VERSION "HIPBNYYYYYYYYYYYYYYYYYYYYYYYYYYYYYYYYYYYYY/4/%%%/4/'%**4YYY///"

NS_ :

BS_:

BU_: WS200 MCN_Powertrain Front_MCN Mid_MCN Rear_MCN IMU_MCN BIM1 BIM2 BIM3 BIM4 Computer BIM5 Rider_Controls GPS MCN1 MCN2 MCN3 Drive_Controls BIM6 BoschABS IMU

BO_ 1024 WS200IDInfo: 8 WS200
 SG_ TritiumID : 0|32@1+ (1,0) [0|0] "" Vector__XXX
 SG_ SerialNumber : 32|32@1+ (1,0) [0|0] "" Vector__XXX

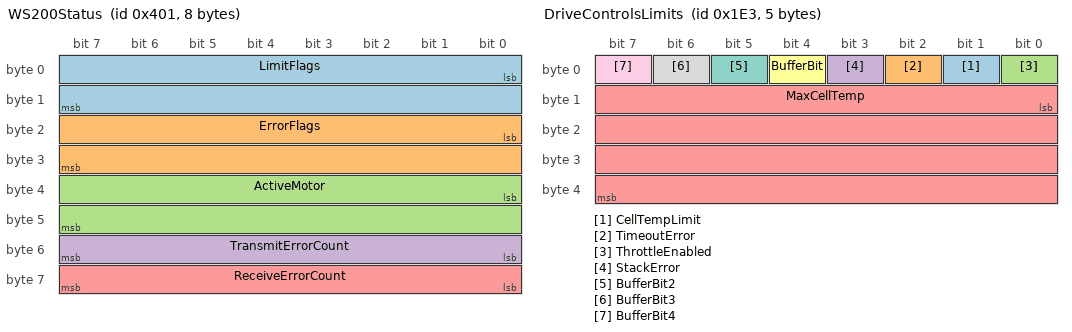
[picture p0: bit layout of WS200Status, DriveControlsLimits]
BO_ 1025 WS200Status: 8 WS200
 SG_ LimitFlags : 0|16@1+ (1,0) [0|0] "" Vector__XXX
 SG_ ErrorFlags : 16|16@1+ (1,0) [0|0] "" Vector__XXX
 SG_ ActiveMotor : 32|16@1+ (1,0) [0|0] "" Vector__XXX
 SG_ TransmitErrorCount : 48|8@1+ (1,0) [0|0] "" Vector__XXX
 SG_ ReceiveErrorCount : 56|8@1+ (1,0) [0|0] "" Vector__XXX

BO_ 1026 WS200BusMeasurement: 8 WS200
 SG_ BusVoltage : 0|32@1- (1,0) [0|0] "" Vector__XXX
 SG_ BusCurrent : 32|32@1- (1,0) [0|0] "" Vector__XXX

BO_ 1027 VelocityMeasurement: 8 WS200
 SG_ MotorVelocity : 0|32@1- (1,0) [0|0] "" Vector__XXX
 SG_ VehicleVelocity : 32|32@1- (1,0) [0|0] "" Vector__XXX

BO_ 1028 PhaseCurrent: 8 WS200
 SG_ PhaseCurrentB : 0|32@1- (1,0) [0|0] "" Vector__XXX
 SG_ PhaseCurrentC : 32|32@1- (1,0) [0|0] "" Vector__XXX

BO_ 1029 MotorVoltage: 8 WS200
 SG_ Vq : 0|32@1- (1,0) [0|0] "" Vector__XXX
 SG_ Vd : 32|32@1- (1,0) [0|0] "" Vector__XXX

BO_ 1030 MotorCurrent: 8 WS200
 SG_ Iq : 0|32@1- (1,0) [0|0] "" Vector__XXX
 SG_ Id : 32|32@1- (1,0) [0|0] "" Vector__XXX

BO_ 1031 MotorBackEMF: 8 WS200
 SG_ BEMFq : 0|32@1- (1,0) [0|0] "" Vector__XXX
 SG_ BEMFd : 32|32@1- (1,0) [0|0] "" Vector__XXX

BO_ 1032 WS200Rail15V: 8 WS200
 SG_ Supply15V : 32|32@1- (1,0) [0|0] "" Vector__XXX
 SG_ Reserved15V : 0|32@1- (1,0) [0|0] "" Vector__XXX

BO_ 1033 WS200LowRail: 8 WS200
 SG_ Rail2V : 0|32@1- (1,0) [0|0] "" Vector__XXX
 SG_ Rail3V : 32|32@1- (1,0) [0|0] "" Vector__XXX

BO_ 1035 WS200MotorTemp: 8 WS200
 SG_ IPMPhaseATemp : 32|32@1- (1,0) [0|0] "" Vector__XXX
 SG_ MotorTemp : 0|32@1- (1,0) [0|0] "" Vector__XXX

BO_ 1036 WS200DSPBoardTemp: 8 WS200
 SG_ IPMPhaseBTemp : 0|32@1- (1,0) [0|0] "" Vector__XXX
 SG_ DSPBoardTemp : 32|32@1- (1,0) [0|0] "" Vector__XXX

BO_ 1037 WS200PhaseCTemp: 8 WS200
 SG_ IMPPhaseCTemp : 32|32@1- (1,0) [0|0] "" Vector__XXX
 SG_ Reserved : 0|32@1- (1,0) [0|0] "" Vector__XXX

BO_ 1038 WS200BusAmpHours: 8 WS200
 SG_ DCBusAmpHours : 32|32@1- (1,0) [0|0] "" Vector__XXX
 SG_ Odometer : 0|32@1- (1,0) [0|0] "" Vector__XXX

BO_ 1039 SlipSpeed: 8 WS200
 SG_ SlipSpeed : 0|32@1- (1,0) [0|0] "" Vector__XXX
 SG_ Reserved : 32|32@1- (1,0) [0|0] "" Vector__XXX

BO_ 551 Steering: 4 MCN1
 SG_ SteeringAngle : 0|32@1- (1,0) [0|0] "" Vector__XXX

BO_ 552 AmbientMeasurements: 8 MCN1
 SG_ AmbientTemp : 0|32@1- (1,0) [0|0] "" Vector__XXX
 SG_ AmbientPressure : 32|32@1- (1,0) [0|0] "" Vector__XXX

BO_ 1281 MotorDriveCommand: 8 Drive_Controls
 SG_ MotorRPMSetpoint : 0|32@1- (1,0) [0|4000] "" Vector__XXX
 SG_ MotorCurrentSetpoint : 32|32@1- (1,0) [0|1] "" Vector__XXX

BO_ 483 DriveControlsLimits: 5 Drive_Controls
 SG_ CellTempLimit : 1|1@1+ (1,0) [0|1] "" Vector__XXX
 SG_ TimeoutError : 2|1@1+ (1,0) [0|1] "" Vector__XXX
 SG_ ThrottleEnabled : 0|1@1+ (1,0) [0|0] "" Vector__XXX
 SG_ StackError : 3|1@1+ (1,0) [0|0] "" Vector__XXX
 SG_ MaxCellTemp : 8|32@1- (1,0) [0|0] "" Vector__XXX
 SG_ BufferBit : 4|1@1+ (1,0) [0|0] "" Vector__XXX
 SG_ BufferBit2 : 5|1@1+ (1,0) [0|0] "" Vector__XXX
 SG_ BufferBit3 : 6|1@1+ (1,0) [0|0] "" Vector__XXX
 SG_ BufferBit4 : 7|1@1+ (1,0) [0|0] "" Vector__XXX

BO_ 750 BIM1Stats1: 6 BIM1
 SG_ BIM1MaxCellVoltage : 0|16@1+ (1,0) [0|0] "" Vector__XXX
 SG_ BIM1MaxCellNumber : 16|8@1+ (1,0) [0|0] "" Vector__XXX
 SG_ BIM1MinCellVoltage : 32|16@1+ (1,0) [0|0] "" Vector__XXX
 SG_ BIM1MinCellNumber : 48|8@1+ (1,0) [0|0] "" Vector__XXX
 SG_ BIM1Stat1reserve : 24|8@1+ (1,0) [0|0] "" Vector__XXX

BO_ 751 BIM1Stats2: 5 BIM1
 SG_ BIM1AvgCellVoltage : 0|16@1+ (1,0) [0|0] "" Vector__XXX
 SG_ BIM1StdDevCellVoltage : 16|16@1+ (1,0) [0|0] "" Vector__XXX
 SG_ BIM1NumOfBalancingCells : 32|8@1+ (1,0) [0|0] "" Vector__XXX

BO_ 752 BIM2Stats1: 6 BIM2
 SG_ BIM2MaxCellVoltage : 0|16@1+ (1,0) [0|0] "" Vector__XXX
 SG_ BIM2MaxCellNumber : 16|8@1+ (1,0) [0|0] "" Vector__XXX
 SG_ BIM2MinCellVoltage : 32|16@1+ (1,0) [0|0] "" Vector__XXX
 SG_ BIM2MinCellNumber : 48|8@1+ (1,0) [0|0] "" Vector__XXX
 SG_ BIM2Stat1reserve : 24|8@1+ (1,0) [0|0] "" Vector__XXX

BO_ 753 BIM2Stats2: 5 BIM2
 SG_ BIM2AvgCellVoltage : 0|16@1+ (1,0) [0|0] "" Vector__XXX
 SG_ BIM2StdDevCellVoltage : 16|16@1+ (1,0) [0|0] "" Vector__XXX
 SG_ BIM2NumOfBalancingCells : 32|8@1+ (1,0) [0|0] "" Vector__XXX

BO_ 754 BIM3Stats1: 6 BIM3
 SG_ BIM3MaxCellVoltage : 0|16@1+ (1,0) [0|0] "" Vector__XXX
 SG_ BIM3MaxCellNumber : 16|8@1+ (1,0) [0|0] "" Vector__XXX
 SG_ BIM3MinCellVoltage : 32|16@1+ (1,0) [0|0] "" Vector__XXX
 SG_ BIM3MinCellNumber : 48|8@1+ (1,0) [0|0] "" Vector__XXX
 SG_ BIM3Stat1reserve : 24|8@1+ (1,0) [0|0] "" Vector__XXX

BO_ 755 BIM3Stats2: 5 BIM3
 SG_ BIM3AvgCellVoltage : 0|16@1+ (1,0) [0|0] "" Vector__XXX
 SG_ BIM3StdDevVoltage : 16|16@1+ (1,0) [0|0] "" Vector__XXX
 SG_ BIM3NumOfBalancingCells : 32|8@1+ (1,0) [0|0] "" Vector__XXX

BO_ 756 BIM4Stats1: 6 BIM4
 SG_ BIM4MaxCellVoltage : 0|16@1+ (1,0) [0|0] "" Vector__XXX
 SG_ BIM4MaxCellNumber : 16|8@1+ (1,0) [0|0] "" Vector__XXX
 SG_ BIM4MinCellVoltage : 32|16@1+ (1,0) [0|0] "" Vector__XXX
 SG_ BIM4MinCellNumber : 48|8@1+ (1,0) [0|0] "" Vector__XXX
 SG_ BIM4Stat1reserve : 24|8@1+ (1,0) [0|0] "" Vector__XXX

BO_ 757 BIM4Stats2: 5 BIM4
 SG_ BIM4AvgCellVoltage : 0|16@1+ (1,0) [0|0] "" Vector__XXX
 SG_ BIM4StdDevVoltage : 16|16@1+ (1,0) [0|0] "" Vector__XXX
 SG_ BIM4NumOfBalancingCells : 32|8@1+ (1,0) [0|0] "" Vector__XXX

BO_ 758 BIM5Stats1: 6 BIM5
 SG_ BIM5MaxCellVoltage : 0|16@1+ (1,0) [0|0] "" Vector__XXX
 SG_ BIM5MaxCellNumber : 16|8@1+ (1,0) [0|0] "" Vector__XXX
 SG_ BIM5MinCellVoltage : 32|16@1+ (1,0) [0|0] "" Vector__XXX
 SG_ BIM5MinCellNumber : 48|8@1+ (1,0) [0|0] "" Vector__XXX
 SG_ BIM5Stat1reserve : 24|8@1+ (1,0) [0|0] "" Vector__XXX

BO_ 759 BIM5Stats2: 5 BIM5
 SG_ BIM5AvgCellVoltage : 0|16@1+ (1,0) [0|0] "" Vector__XXX
 SG_ BIM5StdDevVoltage : 16|16@1+ (1,0) [0|0] "" Vector__XXX
 SG_ BIM5NumOfBalancingCells : 32|8@1+ (1,0) [0|0] "" Vector__XXX

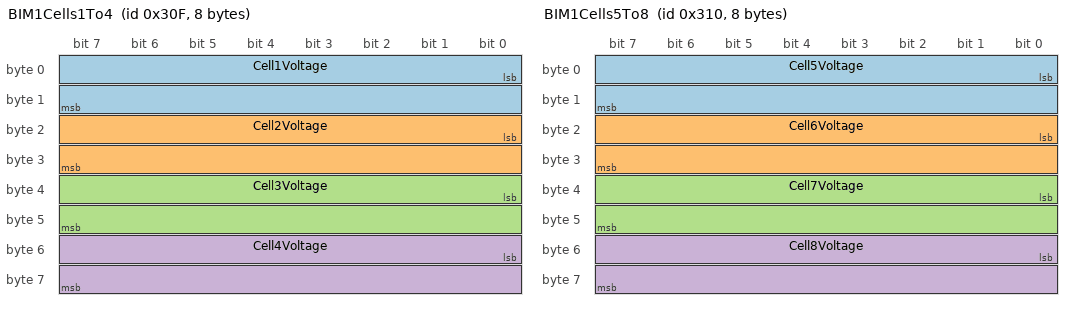
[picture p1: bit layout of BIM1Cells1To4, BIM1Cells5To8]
BO_ 783 BIM1Cells1To4: 8 BIM1
 SG_ Cell1Voltage : 0|16@1- (1,0) [0|0] "" Vector__XXX
 SG_ Cell2Voltage : 16|16@1- (1,0) [0|0] "" Vector__XXX
 SG_ Cell3Voltage : 32|16@1- (1,0) [0|0] "" Vector__XXX
 SG_ Cell4Voltage : 48|16@1- (1,0) [0|0] "" Vector__XXX

BO_ 784 BIM1Cells5To8: 8 BIM1
 SG_ Cell5Voltage : 0|16@1- (1,0) [0|0] "" Vector__XXX
 SG_ Cell6Voltage : 16|16@1- (1,0) [0|0] "" Vector__XXX
 SG_ Cell7Voltage : 32|16@1- (1,0) [0|0] "" Vector__XXX
 SG_ Cell8Voltage : 48|16@1- (1,0) [0|0] "" Vector__XXX

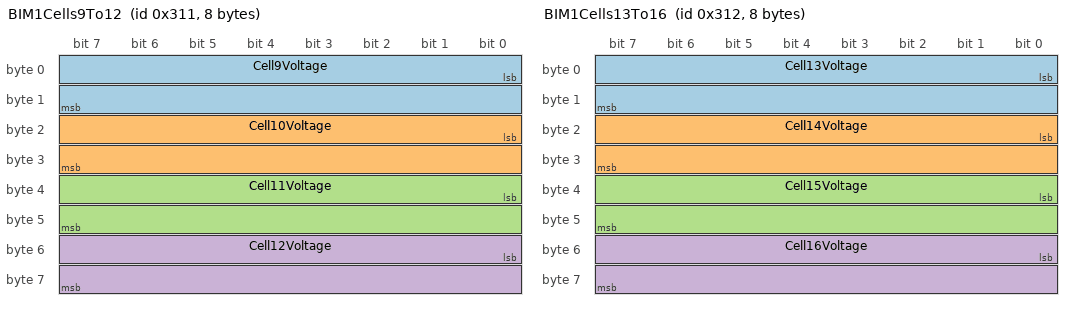
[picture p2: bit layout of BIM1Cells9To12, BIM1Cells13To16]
BO_ 785 BIM1Cells9To12: 8 BIM1
 SG_ Cell9Voltage : 0|16@1- (1,0) [0|0] "" Vector__XXX
 SG_ Cell10Voltage : 16|16@1- (1,0) [0|0] "" Vector__XXX
 SG_ Cell11Voltage : 32|16@1- (1,0) [0|0] "" Vector__XXX
 SG_ Cell12Voltage : 48|16@1- (1,0) [0|0] "" Vector__XXX

BO_ 786 BIM1Cells13To16: 8 BIM1
 SG_ Cell13Voltage : 0|16@1- (1,0) [0|0] "" Vector__XXX
 SG_ Cell14Voltage : 16|16@1- (1,0) [0|0] "" Vector__XXX
 SG_ Cell15Voltage : 32|16@1- (1,0) [0|0] "" Vector__XXX
 SG_ Cell16Voltage : 48|16@1- (1,0) [0|0] "" Vector__XXX

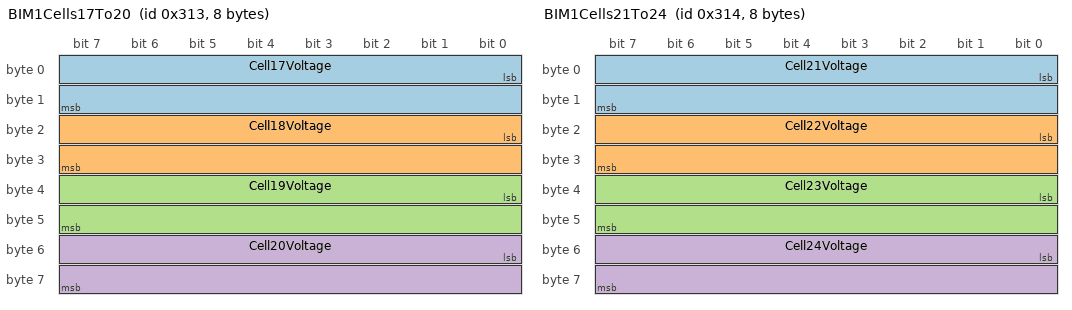
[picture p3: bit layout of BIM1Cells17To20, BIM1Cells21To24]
BO_ 787 BIM1Cells17To20: 8 BIM1
 SG_ Cell17Voltage : 0|16@1- (1,0) [0|0] "" Vector__XXX
 SG_ Cell18Voltage : 16|16@1- (1,0) [0|0] "" Vector__XXX
 SG_ Cell19Voltage : 32|16@1- (1,0) [0|0] "" Vector__XXX
 SG_ Cell20Voltage : 48|16@1- (1,0) [0|0] "" Vector__XXX

BO_ 788 BIM1Cells21To24: 8 BIM1
 SG_ Cell21Voltage : 0|16@1- (1,0) [0|0] "" Vector__XXX
 SG_ Cell22Voltage : 16|16@1- (1,0) [0|0] "" Vector__XXX
 SG_ Cell23Voltage : 32|16@1- (1,0) [0|0] "" Vector__XXX
 SG_ Cell24Voltage : 48|16@1- (1,0) [0|0] "" Vector__XXX

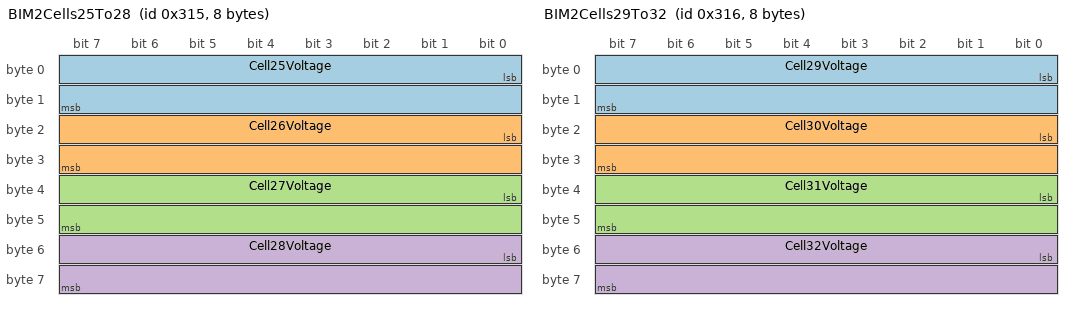
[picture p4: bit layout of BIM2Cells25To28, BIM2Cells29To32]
BO_ 789 BIM2Cells25To28: 8 BIM2
 SG_ Cell25Voltage : 0|16@1- (1,0) [0|0] "" Vector__XXX
 SG_ Cell26Voltage : 16|16@1- (1,0) [0|0] "" Vector__XXX
 SG_ Cell27Voltage : 32|16@1- (1,0) [0|0] "" Vector__XXX
 SG_ Cell28Voltage : 48|16@1- (1,0) [0|0] "" Vector__XXX

BO_ 790 BIM2Cells29To32: 8 BIM2
 SG_ Cell29Voltage : 0|16@1- (1,0) [0|0] "" Vector__XXX
 SG_ Cell30Voltage : 16|16@1- (1,0) [0|0] "" Vector__XXX
 SG_ Cell31Voltage : 32|16@1- (1,0) [0|0] "" Vector__XXX
 SG_ Cell32Voltage : 48|16@1- (1,0) [0|0] "" Vector__XXX

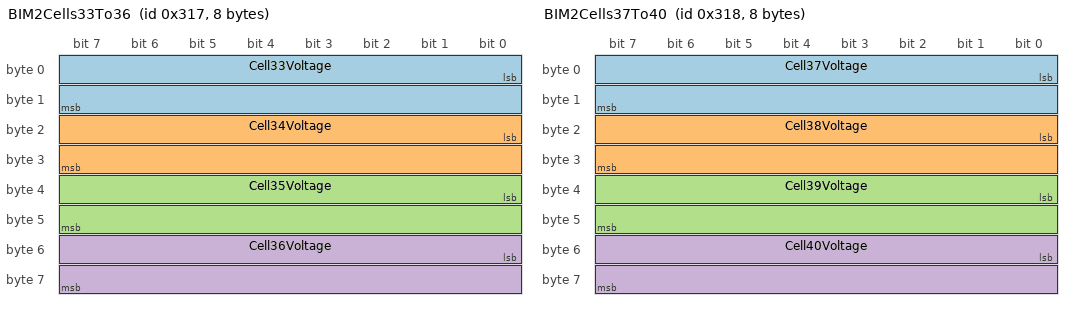
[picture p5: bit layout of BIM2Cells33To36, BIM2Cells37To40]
BO_ 791 BIM2Cells33To36: 8 BIM2
 SG_ Cell33Voltage : 0|16@1- (1,0) [0|0] "" Vector__XXX
 SG_ Cell34Voltage : 16|16@1- (1,0) [0|0] "" Vector__XXX
 SG_ Cell35Voltage : 32|16@1- (1,0) [0|0] "" Vector__XXX
 SG_ Cell36Voltage : 48|16@1- (1,0) [0|0] "" Vector__XXX

BO_ 792 BIM2Cells37To40: 8 BIM2
 SG_ Cell37Voltage : 0|16@1- (1,0) [0|0] "" Vector__XXX
 SG_ Cell38Voltage : 16|16@1- (1,0) [0|0] "" Vector__XXX
 SG_ Cell39Voltage : 32|16@1- (1,0) [0|0] "" Vector__XXX
 SG_ Cell40Voltage : 48|16@1- (1,0) [0|0] "" Vector__XXX

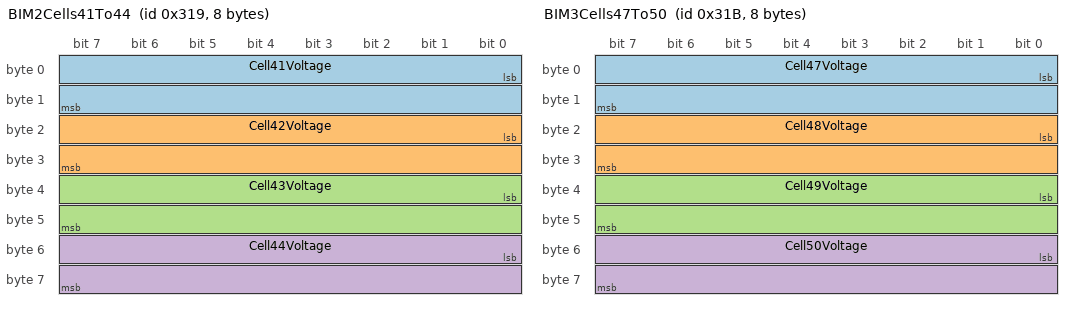
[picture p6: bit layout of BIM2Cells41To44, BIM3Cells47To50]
BO_ 793 BIM2Cells41To44: 8 BIM2
 SG_ Cell41Voltage : 0|16@1- (1,0) [0|0] "" Vector__XXX
 SG_ Cell42Voltage : 16|16@1- (1,0) [0|0] "" Vector__XXX
 SG_ Cell43Voltage : 32|16@1- (1,0) [0|0] "" Vector__XXX
 SG_ Cell44Voltage : 48|16@1- (1,0) [0|0] "" Vector__XXX

BO_ 794 BIM2Cells45To46: 4 BIM2
 SG_ Cell45Voltage : 0|16@1- (1,0) [0|0] "" Vector__XXX
 SG_ Cell46Voltage : 16|16@1- (1,0) [0|0] "" Vector__XXX
 SG_ Cell47Voltage : 32|16@1- (1,0) [0|0] "" Vector__XXX
 SG_ Cell48Voltage : 48|16@1- (1,0) [0|0] "" Vector__XXX

BO_ 795 BIM3Cells47To50: 8 BIM3
 SG_ Cell47Voltage : 0|16@1- (1,0) [0|0] "" Vector__XXX
 SG_ Cell48Voltage : 16|16@1- (1,0) [0|0] "" Vector__XXX
 SG_ Cell49Voltage : 32|16@1- (1,0) [0|0] "" Vector__XXX
 SG_ Cell50Voltage : 48|16@1- (1,0) [0|0] "" Vector__XXX

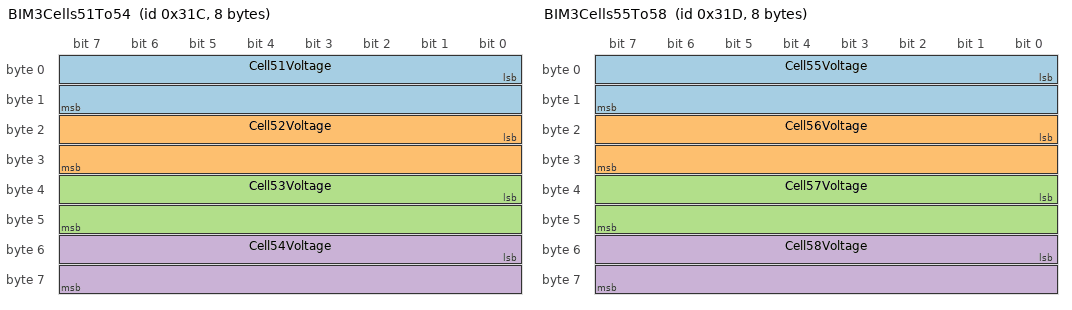
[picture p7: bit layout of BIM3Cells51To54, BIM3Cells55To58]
BO_ 796 BIM3Cells51To54: 8 BIM3
 SG_ Cell51Voltage : 0|16@1- (1,0) [0|0] "" Vector__XXX
 SG_ Cell52Voltage : 16|16@1- (1,0) [0|0] "" Vector__XXX
 SG_ Cell53Voltage : 32|16@1- (1,0) [0|0] "" Vector__XXX
 SG_ Cell54Voltage : 48|16@1- (1,0) [0|0] "" Vector__XXX

BO_ 797 BIM3Cells55To58: 8 BIM3
 SG_ Cell55Voltage : 0|16@1- (1,0) [0|0] "" Vector__XXX
 SG_ Cell56Voltage : 16|16@1- (1,0) [0|0] "" Vector__XXX
 SG_ Cell57Voltage : 32|16@1- (1,0) [0|0] "" Vector__XXX
 SG_ Cell58Voltage : 48|16@1- (1,0) [0|0] "" Vector__XXX

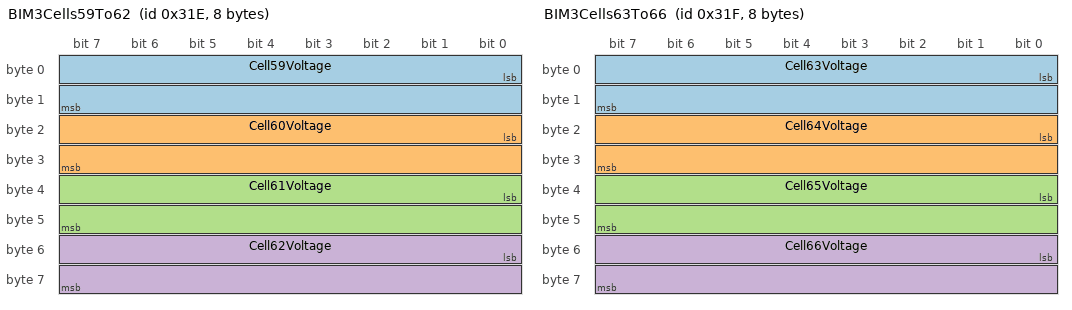
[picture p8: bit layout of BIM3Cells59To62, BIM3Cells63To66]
BO_ 798 BIM3Cells59To62: 8 BIM3
 SG_ Cell59Voltage : 0|16@1- (1,0) [0|0] "" Vector__XXX
 SG_ Cell60Voltage : 16|16@1- (1,0) [0|0] "" Vector__XXX
 SG_ Cell61Voltage : 32|16@1- (1,0) [0|0] "" Vector__XXX
 SG_ Cell62Voltage : 48|16@1- (1,0) [0|0] "" Vector__XXX

BO_ 799 BIM3Cells63To66: 8 BIM3
 SG_ Cell63Voltage : 0|16@1- (1,0) [0|0] "" Vector__XXX
 SG_ Cell64Voltage : 16|16@1- (1,0) [0|0] "" Vector__XXX
 SG_ Cell65Voltage : 32|16@1- (1,0) [0|0] "" Vector__XXX
 SG_ Cell66Voltage : 48|16@1- (1,0) [0|0] "" Vector__XXX

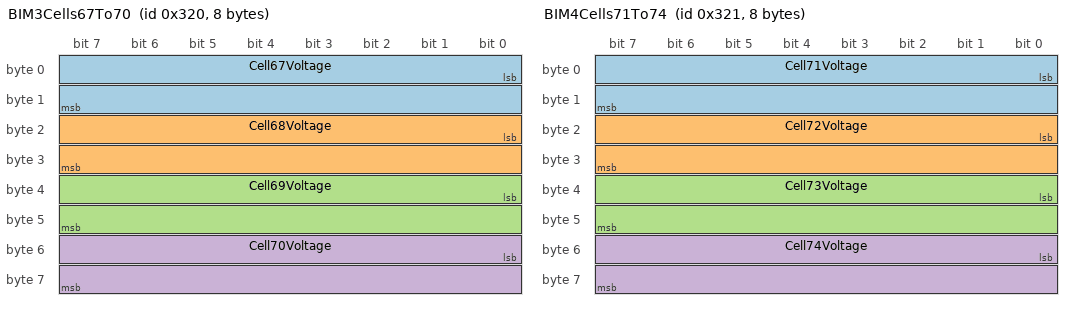
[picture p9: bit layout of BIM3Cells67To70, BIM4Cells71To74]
BO_ 800 BIM3Cells67To70: 8 BIM3
 SG_ Cell67Voltage : 0|16@1- (1,0) [0|0] "" Vector__XXX
 SG_ Cell68Voltage : 16|16@1- (1,0) [0|0] "" Vector__XXX
 SG_ Cell69Voltage : 32|16@1- (1,0) [0|0] "" Vector__XXX
 SG_ Cell70Voltage : 48|16@1- (1,0) [0|0] "" Vector__XXX

BO_ 801 BIM4Cells71To74: 8 BIM4
 SG_ Cell71Voltage : 0|16@1- (1,0) [0|0] "" Vector__XXX
 SG_ Cell72Voltage : 16|16@1- (1,0) [0|0] "" Vector__XXX
 SG_ Cell73Voltage : 32|16@1- (1,0) [0|0] "" Vector__XXX
 SG_ Cell74Voltage : 48|16@1- (1,0) [0|0] "" Vector__XXX

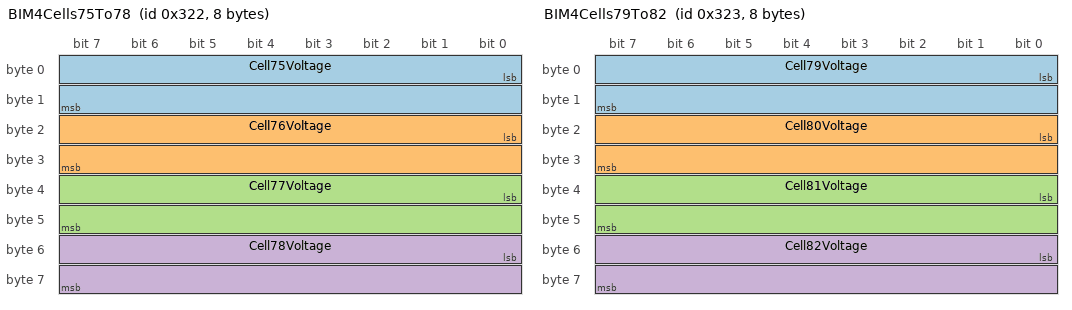
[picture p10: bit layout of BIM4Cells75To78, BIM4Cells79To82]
BO_ 802 BIM4Cells75To78: 8 BIM4
 SG_ Cell75Voltage : 0|16@1- (1,0) [0|0] "" Vector__XXX
 SG_ Cell76Voltage : 16|16@1- (1,0) [0|0] "" Vector__XXX
 SG_ Cell77Voltage : 32|16@1- (1,0) [0|0] "" Vector__XXX
 SG_ Cell78Voltage : 48|16@1- (1,0) [0|0] "" Vector__XXX

BO_ 803 BIM4Cells79To82: 8 BIM4
 SG_ Cell79Voltage : 0|16@1- (1,0) [0|0] "" Vector__XXX
 SG_ Cell80Voltage : 16|16@1- (1,0) [0|0] "" Vector__XXX
 SG_ Cell81Voltage : 32|16@1- (1,0) [0|0] "" Vector__XXX
 SG_ Cell82Voltage : 48|16@1- (1,0) [0|0] "" Vector__XXX

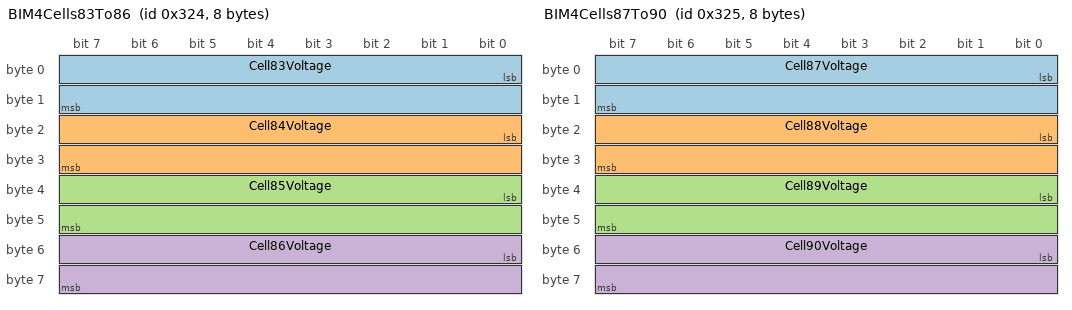
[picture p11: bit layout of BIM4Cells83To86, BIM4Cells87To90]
BO_ 804 BIM4Cells83To86: 8 BIM4
 SG_ Cell83Voltage : 0|16@1- (1,0) [0|0] "" Vector__XXX
 SG_ Cell84Voltage : 16|16@1- (1,0) [0|0] "" Vector__XXX
 SG_ Cell85Voltage : 32|16@1- (1,0) [0|0] "" Vector__XXX
 SG_ Cell86Voltage : 48|16@1- (1,0) [0|0] "" Vector__XXX

BO_ 805 BIM4Cells87To90: 8 BIM4
 SG_ Cell87Voltage : 0|16@1- (1,0) [0|0] "" Vector__XXX
 SG_ Cell88Voltage : 16|16@1- (1,0) [0|0] "" Vector__XXX
 SG_ Cell89Voltage : 32|16@1- (1,0) [0|0] "" Vector__XXX
 SG_ Cell90Voltage : 48|16@1- (1,0) [0|0] "" Vector__XXX

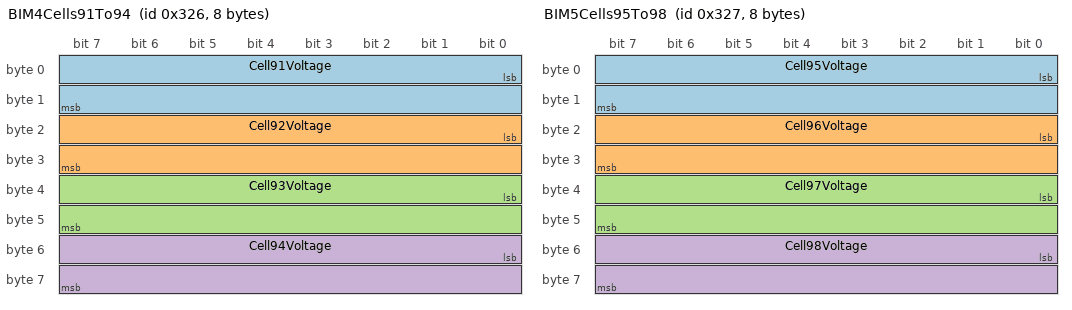
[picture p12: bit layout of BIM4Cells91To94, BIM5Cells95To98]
BO_ 806 BIM4Cells91To94: 8 BIM4
 SG_ Cell91Voltage : 0|16@1- (1,0) [0|0] "" Vector__XXX
 SG_ Cell92Voltage : 16|16@1- (1,0) [0|0] "" Vector__XXX
 SG_ Cell93Voltage : 32|16@1- (1,0) [0|0] "" Vector__XXX
 SG_ Cell94Voltage : 48|16@1- (1,0) [0|0] "" Vector__XXX

BO_ 807 BIM5Cells95To98: 8 BIM5
 SG_ Cell95Voltage : 0|16@1- (1,0) [0|0] "" Vector__XXX
 SG_ Cell96Voltage : 16|16@1- (1,0) [0|0] "" Vector__XXX
 SG_ Cell97Voltage : 32|16@1- (1,0) [0|0] "" Vector__XXX
 SG_ Cell98Voltage : 48|16@1- (1,0) [0|0] "" Vector__XXX

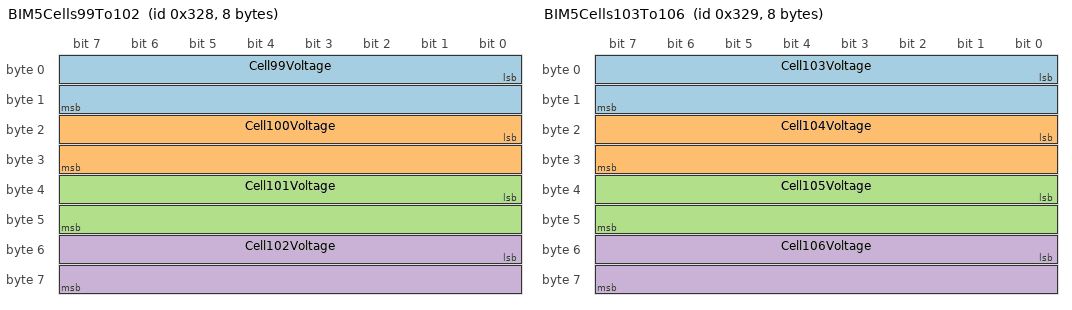
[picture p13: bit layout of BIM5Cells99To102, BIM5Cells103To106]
BO_ 808 BIM5Cells99To102: 8 BIM5
 SG_ Cell99Voltage : 0|16@1- (1,0) [0|0] "" Vector__XXX
 SG_ Cell100Voltage : 16|16@1- (1,0) [0|0] "" Vector__XXX
 SG_ Cell101Voltage : 32|16@1- (1,0) [0|0] "" Vector__XXX
 SG_ Cell102Voltage : 48|16@1- (1,0) [0|0] "" Vector__XXX

BO_ 809 BIM5Cells103To106: 8 BIM5
 SG_ Cell103Voltage : 0|16@1- (1,0) [0|0] "" Vector__XXX
 SG_ Cell104Voltage : 16|16@1- (1,0) [0|0] "" Vector__XXX
 SG_ Cell105Voltage : 32|16@1- (1,0) [0|0] "" Vector__XXX
 SG_ Cell106Voltage : 48|16@1- (1,0) [0|0] "" Vector__XXX

BO_ 826 BIM1Temps2: 8 BIM1
 SG_ CellTemp3 : 0|32@1- (1,0) [0|0] "" Vector__XXX
 SG_ CellTemp4 : 32|32@1- (1,0) [0|0] "" Vector__XXX

BO_ 827 BIM1Temps3: 8 BIM1
 SG_ CellTemp5 : 0|32@1- (1,0) [0|0] "" Vector__XXX
 SG_ CellTemp6 : 32|32@1- (1,0) [0|0] "" Vector__XXX

BO_ 828 BIM1Temps4: 8 BIM1
 SG_ CellTemp7 : 0|32@1- (1,0) [0|0] "" Vector__XXX
 SG_ CellTemp8 : 32|32@1- (1,0) [0|0] "" Vector__XXX

BO_ 829 BIM2Temps1: 8 BIM2
 SG_ CellTemp9 : 0|32@1- (1,0) [0|0] "" Vector__XXX
 SG_ CellTemp10 : 32|32@1- (1,0) [0|0] "" Vector__XXX

BO_ 830 BIM2Temps2: 8 BIM2
 SG_ CellTemp11 : 0|32@1- (1,0) [0|0] "" Vector__XXX
 SG_ CellTemp12 : 32|32@1- (1,0) [0|0] "" Vector__XXX

BO_ 831 BIM2Temps3: 8 BIM2
 SG_ CellTemp13 : 0|32@1- (1,0) [0|0] "" Vector__XXX
 SG_ CellTemp14 : 32|32@1- (1,0) [0|0] "" Vector__XXX

BO_ 832 BIM2Temps4: 8 BIM2
 SG_ CellTemp15 : 0|32@1- (1,0) [0|0] "" Vector__XXX
 SG_ CellTemp16 : 32|32@1- (1,0) [0|0] "" Vector__XXX

BO_ 833 BIM3Temps1: 8 BIM3
 SG_ CellTemp17 : 0|32@1- (1,0) [0|0] "" Vector__XXX
 SG_ CellTemp18 : 32|32@1- (1,0) [0|0] "" Vector__XXX

BO_ 834 BIM3Temps2: 8 BIM3
 SG_ CellTemp19 : 0|32@1- (1,0) [0|0] "" Vector__XXX
 SG_ CellTemp20 : 32|32@1- (1,0) [0|0] "" Vector__XXX

BO_ 835 BIM3Temps3: 8 BIM3
 SG_ CellTemp21 : 0|32@1- (1,0) [0|0] "" Vector__XXX
 SG_ CellTemp22 : 32|32@1- (1,0) [0|0] "" Vector__XXX

BO_ 836 BIM3Temps4: 8 BIM3
 SG_ CellTemp23 : 0|32@1- (1,0) [0|0] "" Vector__XXX
 SG_ CellTemp24 : 32|32@1- (1,0) [0|0] "" Vector__XXX

BO_ 837 BIM4Temps1: 8 BIM4
 SG_ CellTemp25 : 0|32@1- (1,0) [0|0] "" Vector__XXX
 SG_ CellTemp26 : 32|32@1- (1,0) [0|0] "" Vector__XXX

BO_ 838 BIM4Temps2: 8 BIM4
 SG_ CellTemp27 : 0|32@1- (1,0) [0|0] "" Vector__XXX
 SG_ CellTemp28 : 32|32@1- (1,0) [0|0] "" Vector__XXX

BO_ 839 BIM4Temps3: 8 BIM4
 SG_ CellTemp29 : 0|32@1- (1,0) [0|0] "" Vector__XXX
 SG_ CellTemp30 : 32|32@1- (1,0) [0|0] "" Vector__XXX

BO_ 840 BIM4Temps4: 8 BIM4
 SG_ CellTemp31 : 0|32@1- (1,0) [0|0] "" Vector__XXX
 SG_ CellTemp32 : 32|32@1- (1,0) [0|0] "" Vector__XXX

BO_ 841 BIM5Temps1: 8 BIM5
 SG_ CellTemp33 : 0|32@1- (1,0) [0|0] "" Vector__XXX
 SG_ CellTemp34 : 32|32@1- (1,0) [0|0] "" Vector__XXX

BO_ 842 BIM5Temps2: 8 BIM5
 SG_ CellTemp35 : 0|32@1- (1,0) [0|0] "" Vector__XXX
 SG_ CellTemp36 : 32|32@1- (1,0) [0|0] "" Vector__XXX

BO_ 843 BIM5Temps3: 8 BIM5
 SG_ CellTemp37 : 0|32@1- (1,0) [0|0] "" Vector__XXX
 SG_ CellTemp38 : 32|32@1- (1,0) [0|0] "" Vector__XXX

BO_ 844 BIM5Temps4: 8 BIM5
 SG_ CellTemp39 : 0|32@1- (1,0) [0|0] "" Vector__XXX
 SG_ CellTemp40 : 32|32@1- (1,0) [0|0] "" Vector__XXX

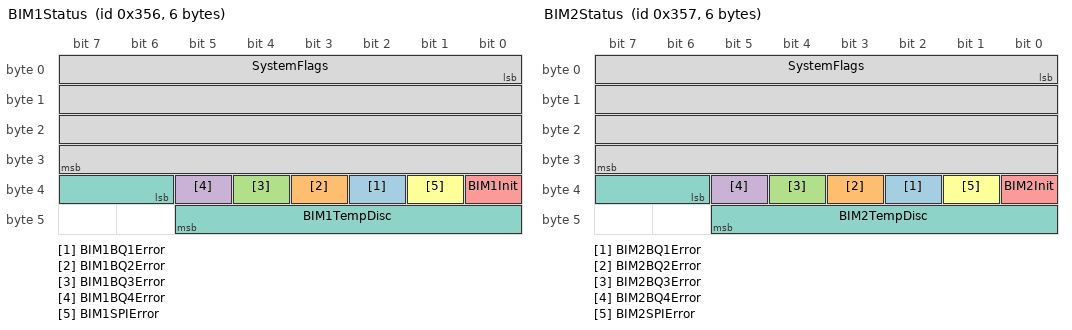
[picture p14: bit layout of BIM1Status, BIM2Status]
BO_ 854 BIM1Status: 6 BIM1
 SG_ BIM1BQ1Error : 34|1@1+ (1,0) [0|0] "" Vector__XXX
 SG_ BIM1BQ2Error : 35|1@1+ (1,0) [0|0] "" Vector__XXX
 SG_ BIM1BQ3Error : 36|1@1+ (1,0) [0|0] "" Vector__XXX
 SG_ BIM1BQ4Error : 37|1@1+ (1,0) [0|0] "" Vector__XXX
 SG_ BIM1Init : 32|1@1+ (1,0) [0|0] "" Vector__XXX
 SG_ BIM1SPIError : 33|1@1+ (1,0) [0|0] "" Vector__XXX
 SG_ BIM1TempDisc : 38|8@1+ (1,0) [0|0] "" Vector__XXX
 SG_ SystemFlags : 0|32@1+ (1,0) [0|0] "" Vector__XXX

BO_ 855 BIM2Status: 6 BIM2
 SG_ BIM2BQ1Error : 34|1@1+ (1,0) [0|0] "" Vector__XXX
 SG_ BIM2BQ2Error : 35|1@1+ (1,0) [0|0] "" Vector__XXX
 SG_ BIM2BQ3Error : 36|1@1+ (1,0) [0|0] "" Vector__XXX
 SG_ BIM2BQ4Error : 37|1@1+ (1,0) [0|0] "" Vector__XXX
 SG_ BIM2Init : 32|1@1+ (1,0) [0|0] "" Vector__XXX
 SG_ BIM2SPIError : 33|1@1+ (1,0) [0|0] "" Vector__XXX
 SG_ BIM2TempDisc : 38|8@1+ (1,0) [0|0] "" Vector__XXX
 SG_ SystemFlags : 0|32@1+ (1,0) [0|0] "" Vector__XXX

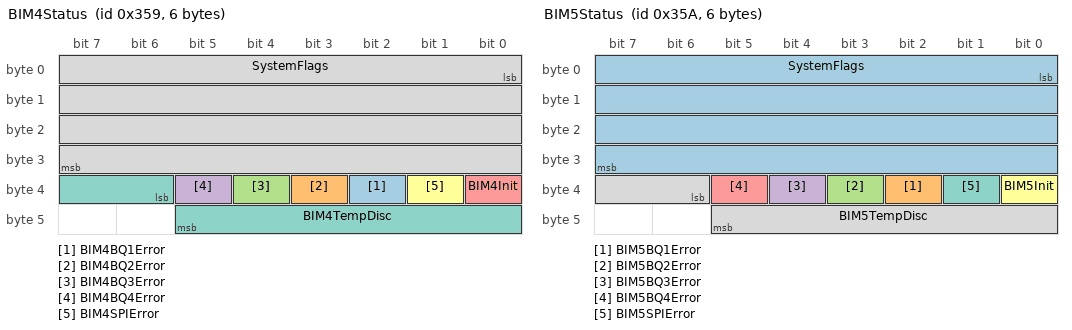
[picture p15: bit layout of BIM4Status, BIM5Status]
BO_ 857 BIM4Status: 6 BIM4
 SG_ BIM4BQ1Error : 34|1@1+ (1,0) [0|0] "" Vector__XXX
 SG_ BIM4BQ2Error : 35|1@1+ (1,0) [0|0] "" Vector__XXX
 SG_ BIM4BQ3Error : 36|1@1+ (1,0) [0|0] "" Vector__XXX
 SG_ BIM4BQ4Error : 37|1@1+ (1,0) [0|0] "" Vector__XXX
 SG_ BIM4Init : 32|1@1+ (1,0) [0|0] "" Vector__XXX
 SG_ BIM4SPIError : 33|1@1+ (1,0) [0|0] "" Vector__XXX
 SG_ BIM4TempDisc : 38|8@1+ (1,0) [0|0] "" Vector__XXX
 SG_ SystemFlags : 0|32@1+ (1,0) [0|0] "" Vector__XXX

BO_ 858 BIM5Status: 6 BIM5
 SG_ SystemFlags : 0|32@1- (1,0) [0|0] "" Vector__XXX
 SG_ BIM5BQ1Error : 34|1@1+ (1,0) [0|0] "" Vector__XXX
 SG_ BIM5BQ2Error : 35|1@1+ (1,0) [0|0] "" Vector__XXX
 SG_ BIM5BQ3Error : 36|1@1+ (1,0) [0|0] "" Vector__XXX
 SG_ BIM5BQ4Error : 37|1@1+ (1,0) [0|0] "" Vector__XXX
 SG_ BIM5Init : 32|1@1+ (1,0) [0|0] "" Vector__XXX
 SG_ BIM5SPIError : 33|1@1+ (1,0) [0|0] "" Vector__XXX
 SG_ BIM5TempDisc : 38|8@1+ (1,0) [0|0] "" Vector__XXX

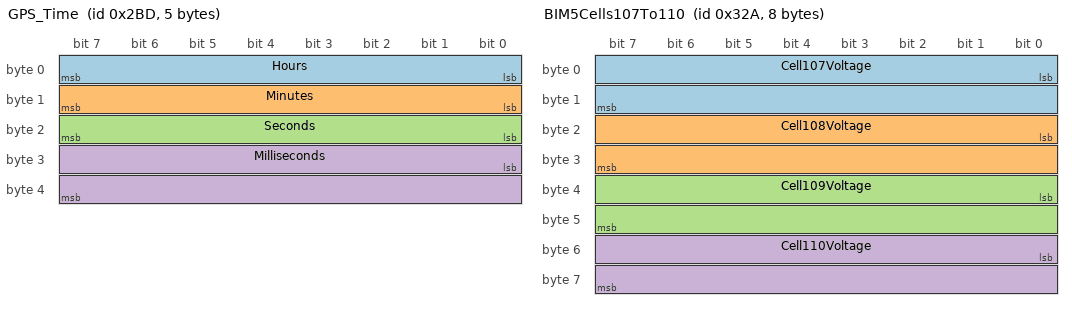
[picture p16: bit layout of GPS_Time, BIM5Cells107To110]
BO_ 701 GPS_Time: 5 GPS
 SG_ Hours : 0|8@1+ (1,0) [0|0] "" Vector__XXX
 SG_ Minutes : 8|8@1+ (1,0) [0|0] "" Vector__XXX
 SG_ Seconds : 16|8@1+ (1,0) [0|0] "" Vector__XXX
 SG_ Milliseconds : 24|16@1+ (1,0) [0|0] "" Vector__XXX

BO_ 702 GPS_Longitude: 5 GPS
 SG_ Direction : 32|8@1+ (1,0) [0|0] "" Vector__XXX
 SG_ Longitude : 0|32@1- (1,0) [0|0] "" Vector__XXX

BO_ 706 GPS_Speed: 4 GPS
 SG_ Speed : 0|32@1- (1,0) [0|0] "" Vector__XXX

BO_ 700 GPS_Date: 4 GPS
 SG_ Day : 0|8@1+ (1,0) [0|0] "" Vector__XXX
 SG_ Month : 8|8@1+ (1,0) [0|0] "" Vector__XXX
 SG_ Year : 16|16@1+ (1,0) [0|0] "" Vector__XXX

BO_ 703 GPS_Latitude: 5 GPS
 SG_ Latitude : 0|32@1- (1,0) [0|0] "" Vector__XXX
 SG_ Direction : 32|8@1+ (1,0) [0|0] "" Vector__XXX

BO_ 704 GPS_Altitude: 4 GPS
 SG_ Altitude : 0|32@1- (1,0) [0|0] "" Vector__XXX

BO_ 705 GPS_Precision: 5 GPS
 SG_ HDOP : 0|32@1- (1,0) [0|0] "" Vector__XXX
 SG_ Num_Satellites : 32|8@1+ (1,0) [0|0] "" Vector__XXX

BO_ 550 SuspensionTravels: 8 MCN1
 SG_ FrontSuspensionTravel : 0|32@1- (1,0) [0|0] "" Vector__XXX
 SG_ RearSuspensionTravel : 32|32@1- (1,0) [0|0] "" Vector__XXX

BO_ 553 CoolantPressures: 4 MCN1
 SG_ MotorInletPressure : 0|32@1- (1,0) [0|0] "" Vector__XXX

BO_ 554 MCN1Heartbeat: 8 MCN1
 SG_ SystemFlags : 0|32@1- (1,0) [0|0] "" Vector__XXX

BO_ 555 MCN1Command: 8 MCN1

BO_ 600 MotorCoolantTemps: 8 MCN2
 SG_ MotorCoolantInletTemp : 0|32@1- (1,0) [0|0] "" Vector__XXX
 SG_ MototCoolantOutletTemp : 32|32@1- (1,0) [0|0] "" Vector__XXX

BO_ 601 ControllerCoolantTemps: 8 MCN2
 SG_ ControllerCoolantInletTemp : 0|32@1- (1,0) [0|0] "" Vector__XXX
 SG_ ControllerCoolantOutetTemp : 32|32@1- (1,0) [0|0] "" Vector__XXX

BO_ 602 ContactorBoxTemp: 4 MCN2
 SG_ ContactorBoxTemp : 0|32@1- (1,0) [0|0] "" Vector__XXX

BO_ 603 CoolantFlows: 8 MCN2
 SG_ ControllerCoolantFlowRate : 0|32@1- (1,0) [0|0] "" Vector__XXX
 SG_ MotorCoolantFlowRate : 32|32@1- (1,0) [0|0] "" Vector__XXX

BO_ 604 MCN2Heartbeat: 8 MCN2
 SG_ SystemFlags : 0|32@1- (1,0) [0|0] "" Vector__XXX

BO_ 605 MCN2Command: 0 MCN2

BO_ 650 TireTemperatures: 8 MCN3
 SG_ FrontTireTemperature : 0|32@1- (1,0) [0|0] "" Vector__XXX
 SG_ RearTireTemperature : 32|32@1- (1,0) [0|0] "" Vector__XXX

BO_ 651 FlexSensorBank1: 8 MCN3
 SG_ FlexSensor1 : 0|32@1- (1,0) [0|0] "" Vector__XXX
 SG_ FlexSensor2 : 32|32@1- (1,0) [0|0] "" Vector__XXX

BO_ 652 FlexSensorBank2: 4 MCN3
 SG_ FlexSensor3 : 0|32@1- (1,0) [0|0] "" Vector__XXX

BO_ 653 MCN3Heartbeat: 8 MCN3
 SG_ SystemFlags : 0|32@1- (1,0) [0|0] "" Vector__XXX

BO_ 654 MCN3Command: 0 MCN3

BO_ 760 BIM6Stats1: 6 BIM6
 SG_ BIM6MaxCellNumber : 16|8@1+ (1,0) [0|0] "" Vector__XXX
 SG_ BIM6MaxCellVoltage : 0|16@1+ (1,0) [0|0] "" Vector__XXX
 SG_ BIM6MinCellNumber : 48|8@1+ (1,0) [0|0] "" Vector__XXX
 SG_ BIM6MinCellVoltage : 32|16@1+ (1,0) [0|0] "" Vector__XXX
 SG_ BIM6Stat1reserve : 24|8@1+ (1,0) [0|0] "" Vector__XXX

BO_ 761 BIM6Stats2: 5 BIM6
 SG_ BIM6AvgCellVoltage : 0|16@1+ (1,0) [0|0] "" Vector__XXX
 SG_ BIM6NumOfBalancingCells : 32|8@1+ (1,0) [0|0] "" Vector__XXX
 SG_ BIM6StdDevVoltage : 16|16@1+ (1,0) [0|0] "" Vector__XXX

BO_ 810 BIM5Cells107To110: 8 BIM5
 SG_ Cell107Voltage : 0|16@1+ (1,0) [0|0] "" Vector__XXX
 SG_ Cell108Voltage : 16|16@1+ (1,0) [0|0] "" Vector__XXX
 SG_ Cell109Voltage : 32|16@1+ (1,0) [0|0] "" Vector__XXX
 SG_ Cell110Voltage : 48|16@1+ (1,0) [0|0] "" Vector__XXX

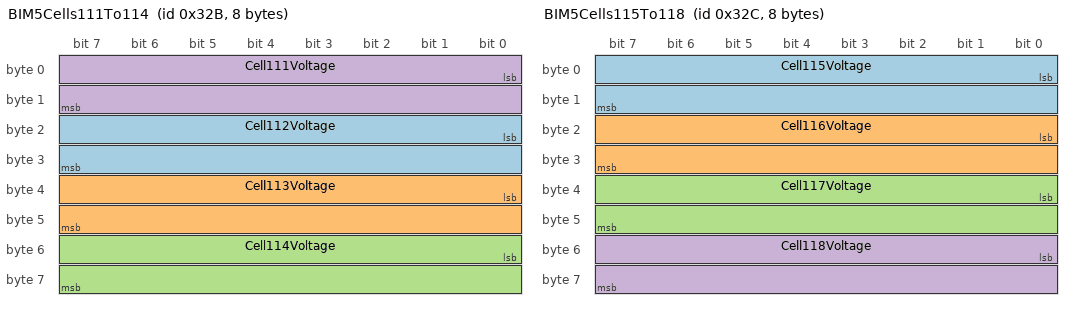
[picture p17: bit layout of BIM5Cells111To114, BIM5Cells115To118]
BO_ 811 BIM5Cells111To114: 8 BIM5
 SG_ Cell112Voltage : 16|16@1+ (1,0) [0|0] "" Vector__XXX
 SG_ Cell113Voltage : 32|16@1+ (1,0) [0|0] "" Vector__XXX
 SG_ Cell114Voltage : 48|16@1+ (1,0) [0|0] "" Vector__XXX
 SG_ Cell111Voltage : 0|16@1+ (1,0) [0|0] "" Vector__XXX

BO_ 812 BIM5Cells115To118: 8 BIM5
 SG_ Cell115Voltage : 0|16@1+ (1,0) [0|0] "" Vector__XXX
 SG_ Cell116Voltage : 16|16@1+ (1,0) [0|0] "" Vector__XXX
 SG_ Cell117Voltage : 32|16@1+ (1,0) [0|0] "" Vector__XXX
 SG_ Cell118Voltage : 48|16@1+ (1,0) [0|0] "" Vector__XXX

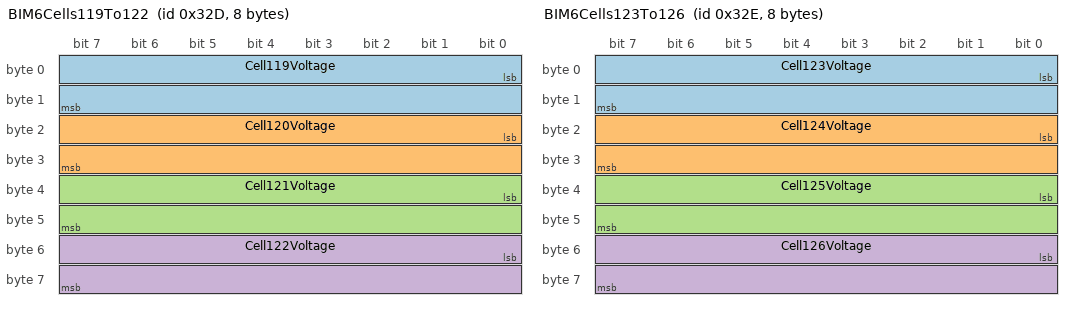
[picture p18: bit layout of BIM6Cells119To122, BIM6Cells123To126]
BO_ 813 BIM6Cells119To122: 8 BIM6
 SG_ Cell119Voltage : 0|16@1+ (1,0) [0|0] "" Vector__XXX
 SG_ Cell120Voltage : 16|16@1+ (1,0) [0|0] "" Vector__XXX
 SG_ Cell121Voltage : 32|16@1+ (1,0) [0|0] "" Vector__XXX
 SG_ Cell122Voltage : 48|16@1+ (1,0) [0|0] "" Vector__XXX

BO_ 814 BIM6Cells123To126: 8 BIM6
 SG_ Cell123Voltage : 0|16@1+ (1,0) [0|0] "" Vector__XXX
 SG_ Cell124Voltage : 16|16@1+ (1,0) [0|0] "" Vector__XXX
 SG_ Cell125Voltage : 32|16@1+ (1,0) [0|0] "" Vector__XXX
 SG_ Cell126Voltage : 48|16@1+ (1,0) [0|0] "" Vector__XXX

BO_ 815 BIM6Cells127To130: 8 BIM6
 SG_ Cell127Voltage : 0|16@1+ (1,0) [0|0] "" Vector__XXX
 SG_ Cell128Voltage : 16|16@1+ (1,0) [0|0] "" Vector__XXX
 SG_ Cell129Voltage : 32|16@1+ (1,0) [0|0] "" Vector__XXX
 SG_ Cell130Voltage : 48|16@1+ (1,0) [0|0] "" Vector__XXX

BO_ 816 BIM6Cells131To134: 8 BIM6
 SG_ Cell131Voltage : 0|16@1+ (1,0) [0|0] "" Vector__XXX
 SG_ Cell132Voltage : 16|16@1+ (1,0) [0|0] "" Vector__XXX
 SG_ Cell133Voltage : 32|16@1+ (1,0) [0|0] "" Vector__XXX
 SG_ Cell134Voltage : 48|16@1+ (1,0) [0|0] "" Vector__XXX

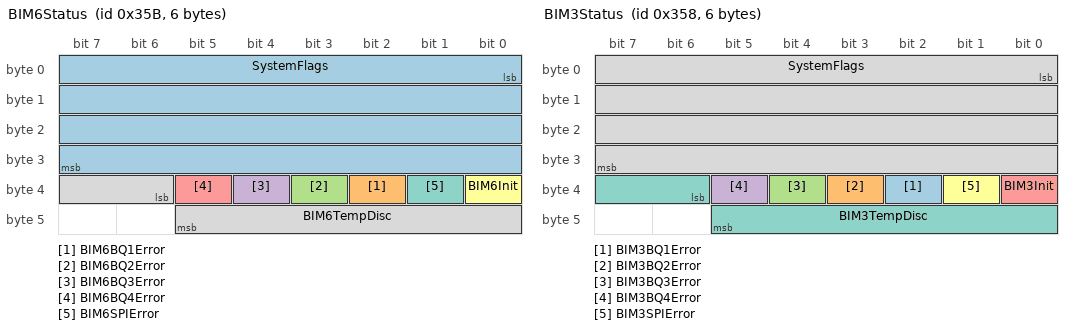
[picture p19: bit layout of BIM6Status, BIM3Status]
BO_ 859 BIM6Status: 6 BIM6
 SG_ SystemFlags : 0|32@1- (1,0) [0|0] "" Vector__XXX
 SG_ BIM6BQ1Error : 34|1@1+ (1,0) [0|0] "" Vector__XXX
 SG_ BIM6BQ2Error : 35|1@1+ (1,0) [0|0] "" Vector__XXX
 SG_ BIM6BQ3Error : 36|1@1+ (1,0) [0|0] "" Vector__XXX
 SG_ BIM6BQ4Error : 37|1@1+ (1,0) [0|0] "" Vector__XXX
 SG_ BIM6Init : 32|1@1+ (1,0) [0|0] "" Vector__XXX
 SG_ BIM6SPIError : 33|1@1+ (1,0) [0|0] "" Vector__XXX
 SG_ BIM6TempDisc : 38|8@1+ (1,0) [0|0] "" Vector__XXX

BO_ 856 BIM3Status: 6 BIM3
 SG_ BIM3BQ1Error : 34|1@1+ (1,0) [0|0] "" Vector__XXX
 SG_ BIM3BQ2Error : 35|1@1+ (1,0) [0|0] "" Vector__XXX
 SG_ BIM3BQ3Error : 36|1@1+ (1,0) [0|0] "" Vector__XXX
 SG_ BIM3BQ4Error : 37|1@1+ (1,0) [0|0] "" Vector__XXX
 SG_ BIM3Init : 32|1@1+ (1,0) [0|0] "" Vector__XXX
 SG_ BIM3SPIError : 33|1@1+ (1,0) [0|0] "" Vector__XXX
 SG_ BIM3TempDisc : 38|8@1+ (1,0) [0|0] "" Vector__XXX
 SG_ SystemFlags : 0|32@1+ (1,0) [0|0] "" Vector__XXX

BO_ 845 BIM6Temps1: 8 BIM6
 SG_ CellTemp41 : 0|32@1- (1,0) [0|0] "" Vector__XXX
 SG_ CellTemp42 : 32|32@1- (1,0) [0|0] "" Vector__XXX

BO_ 846 BIM6Temps2: 8 BIM6
 SG_ CellTemp43 : 0|32@1- (1,0) [0|0] "" Vector__XXX
 SG_ CellTemp44 : 32|32@1- (1,0) [0|0] "" Vector__XXX

BO_ 847 BIM6Temps3: 8 BIM6
 SG_ CellTemp45 : 0|32@1- (1,0) [0|0] "" Vector__XXX
 SG_ CellTemp46 : 32|32@1- (1,0) [0|0] "" Vector__XXX

BO_ 848 BIM6Temps4: 8 BIM6
 SG_ CellTemp47 : 0|32@1- (1,0) [0|0] "" Vector__XXX
 SG_ CellTemp48 : 32|32@1- (1,0) [0|0] "" Vector__XXX

BO_ 861 BIM1Command: 8 BIM1

BO_ 862 BIM2Command: 8 BIM2

BO_ 863 BIM3Command: 8 BIM3

BO_ 864 BIM4Command: 8 BIM4

BO_ 865 BIM5Command: 8 BIM5

BO_ 866 BIM6Command: 8 BIM6

BO_ 1034 WS200Reserved: 8 WS200

BO_ 485 RawThrottleInput: 4 Drive_Controls
 SG_ RawThrottleInput : 0|32@1- (1,0) [0|1] "" Vector__XXX

BO_ 500 FrontWheel: 4 BoschABS

BO_ 501 FrontBrake: 4 BoschABS

BO_ 825 BIM1Temps1: 8 BIM1
 SG_ CellTemp1 : 0|32@1- (1,0) [0|0] "" Vector__XXX
 SG_ CellTemp2 : 32|32@1- (1,0) [0|0] "" Vector__XXX

BO_ 372 IMUYaw: 8 IMU
 SG_ YawRate : 0|16@1- (1,0) [0|0] "" Vector__XXX
 SG_ YawStat : 16|8@1- (1,0) [0|0] "" Vector__XXX
 SG_ AccY : 32|16@1- (1,0) [0|0] "" Vector__XXX
 SG_ AccYStat : 48|8@1- (1,0) [0|0] "" Vector__XXX

BO_ 376 IMURoll: 8 IMU
 SG_ RollStat : 16|8@1- (1,0) [0|0] "" Vector__XXX
 SG_ AccX : 32|16@1- (1,0) [0|0] "" Vector__XXX
 SG_ AccXStat : 48|8@1- (1,0) [0|0] "" Vector__XXX
 SG_ RollRate : 0|16@1- (1,0) [0|0] "" Vector__XXX

CM_ SG_ 1025 ActiveMotor "[0,10]";
CM_ BO_ 783 "RTR";
CM_ BO_ 784 "RTR";
CM_ BO_ 785 "RTR";
CM_ BO_ 786 "RTR";
CM_ BO_ 787 "RTR";
CM_ BO_ 788 "RTR";
CM_ BO_ 789 "RTR";
CM_ BO_ 790 "RTR";
CM_ BO_ 791 "RTR";
CM_ BO_ 792 "RTR";
CM_ BO_ 793 "RTR";
CM_ BO_ 794 "RTR";
CM_ BO_ 795 "RTR";
CM_ BO_ 796 "RTR";
CM_ BO_ 797 "RTR";
CM_ BO_ 798 "RTR";
CM_ BO_ 799 "RTR";
CM_ BO_ 800 "RTR";
CM_ BO_ 801 "RTR";
CM_ BO_ 802 "RTR";
CM_ BO_ 803 "RTR";
CM_ BO_ 804 "RTR";
CM_ BO_ 805 "RTR";
CM_ BO_ 806 "RTR";
CM_ BO_ 807 "RTR";
CM_ BO_ 808 "RTR";
CM_ BO_ 809 "RTR";
CM_ BO_ 555 "RTR";
CM_ BO_ 605 "RTR";
CM_ BO_ 654 "RTR";
CM_ BO_ 810 "RTR";
CM_ BO_ 811 "RTR";
CM_ BO_ 812 "RTR";
CM_ BO_ 813 "RTR";
CM_ BO_ 814 "RTR";
CM_ BO_ 815 "RTR";
CM_ BO_ 816 "RTR";
CM_ BO_ 861 "RTR";
CM_ BO_ 862 "RTR";
CM_ BO_ 863 "RTR";
CM_ BO_ 864 "RTR";
CM_ BO_ 865 "RTR";
CM_ BO_ 866 "RTR";
VAL_ 702 Direction 87 "W" 69 "E" ;
VAL_ 703 Direction 78 "N" 83 "S" ;
SIG_VALTYPE_ 1026 BusVoltage : 1;
SIG_VALTYPE_ 1026 BusCurrent : 1;
SIG_VALTYPE_ 1027 MotorVelocity : 1;
SIG_VALTYPE_ 1027 VehicleVelocity : 1;
SIG_VALTYPE_ 1028 PhaseCurrentB : 1;
SIG_VALTYPE_ 1028 PhaseCurrentC : 1;
SIG_VALTYPE_ 1029 Vq : 1;
SIG_VALTYPE_ 1029 Vd : 1;
SIG_VALTYPE_ 1030 Iq : 1;
SIG_VALTYPE_ 1030 Id : 1;
SIG_VALTYPE_ 1031 BEMFq : 1;
SIG_VALTYPE_ 1031 BEMFd : 1;
SIG_VALTYPE_ 1032 Supply15V : 1;
SIG_VALTYPE_ 1032 Reserved15V : 1;
SIG_VALTYPE_ 1033 Rail2V : 1;
SIG_VALTYPE_ 1033 Rail3V : 1;
SIG_VALTYPE_ 1035 IPMPhaseATemp : 1;
SIG_VALTYPE_ 1035 MotorTemp : 1;
SIG_VALTYPE_ 1036 IPMPhaseBTemp : 1;
SIG_VALTYPE_ 1036 DSPBoardTemp : 1;
SIG_VALTYPE_ 1037 IMPPhaseCTemp : 1;
SIG_VALTYPE_ 1037 Reserved : 1;
SIG_VALTYPE_ 1038 DCBusAmpHours : 1;
SIG_VALTYPE_ 1038 Odometer : 1;
SIG_VALTYPE_ 1039 SlipSpeed : 1;
SIG_VALTYPE_ 1039 Reserved : 1;
SIG_VALTYPE_ 551 SteeringAngle : 1;
SIG_VALTYPE_ 552 AmbientTemp : 1;
SIG_VALTYPE_ 552 AmbientPressure : 1;
SIG_VALTYPE_ 1281 MotorRPMSetpoint : 1;
SIG_VALTYPE_ 1281 MotorCurrentSetpoint : 1;
SIG_VALTYPE_ 483 MaxCellTemp : 1;
SIG_VALTYPE_ 826 CellTemp3 : 1;
SIG_VALTYPE_ 826 CellTemp4 : 1;
SIG_VALTYPE_ 827 CellTemp5 : 1;
SIG_VALTYPE_ 827 CellTemp6 : 1;
SIG_VALTYPE_ 828 CellTemp7 : 1;
SIG_VALTYPE_ 828 CellTemp8 : 1;
SIG_VALTYPE_ 829 CellTemp9 : 1;
SIG_VALTYPE_ 829 CellTemp10 : 1;
SIG_VALTYPE_ 830 CellTemp11 : 1;
SIG_VALTYPE_ 830 CellTemp12 : 1;
SIG_VALTYPE_ 831 CellTemp13 : 1;
SIG_VALTYPE_ 831 CellTemp14 : 1;
SIG_VALTYPE_ 832 CellTemp15 : 1;
SIG_VALTYPE_ 832 CellTemp16 : 1;
SIG_VALTYPE_ 833 CellTemp17 : 1;
SIG_VALTYPE_ 833 CellTemp18 : 1;
SIG_VALTYPE_ 834 CellTemp19 : 1;
SIG_VALTYPE_ 834 CellTemp20 : 1;
SIG_VALTYPE_ 835 CellTemp21 : 1;
SIG_VALTYPE_ 835 CellTemp22 : 1;
SIG_VALTYPE_ 836 CellTemp23 : 1;
SIG_VALTYPE_ 836 CellTemp24 : 1;
SIG_VALTYPE_ 837 CellTemp25 : 1;
SIG_VALTYPE_ 837 CellTemp26 : 1;
SIG_VALTYPE_ 838 CellTemp27 : 1;
SIG_VALTYPE_ 838 CellTemp28 : 1;
SIG_VALTYPE_ 839 CellTemp29 : 1;
SIG_VALTYPE_ 839 CellTemp30 : 1;
SIG_VALTYPE_ 840 CellTemp31 : 1;
SIG_VALTYPE_ 840 CellTemp32 : 1;
SIG_VALTYPE_ 841 CellTemp33 : 1;
SIG_VALTYPE_ 841 CellTemp34 : 1;
SIG_VALTYPE_ 842 CellTemp35 : 1;
SIG_VALTYPE_ 842 CellTemp36 : 1;
SIG_VALTYPE_ 843 CellTemp37 : 1;
SIG_VALTYPE_ 843 CellTemp38 : 1;
SIG_VALTYPE_ 844 CellTemp39 : 1;
SIG_VALTYPE_ 844 CellTemp40 : 1;
SIG_VALTYPE_ 858 SystemFlags : 1;
SIG_VALTYPE_ 702 Longitude : 1;
SIG_VALTYPE_ 706 Speed : 1;
SIG_VALTYPE_ 703 Latitude : 1;
SIG_VALTYPE_ 704 Altitude : 1;
SIG_VALTYPE_ 705 HDOP : 1;
SIG_VALTYPE_ 550 FrontSuspensionTravel : 1;
SIG_VALTYPE_ 550 RearSuspensionTravel : 1;
SIG_VALTYPE_ 553 MotorInletPressure : 1;
SIG_VALTYPE_ 554 SystemFlags : 1;
SIG_VALTYPE_ 600 MotorCoolantInletTemp : 1;
SIG_VALTYPE_ 600 MototCoolantOutletTemp : 1;
SIG_VALTYPE_ 601 ControllerCoolantInletTemp : 1;
SIG_VALTYPE_ 601 ControllerCoolantOutetTemp : 1;
SIG_VALTYPE_ 602 ContactorBoxTemp : 1;
SIG_VALTYPE_ 603 ControllerCoolantFlowRate : 1;
SIG_VALTYPE_ 603 MotorCoolantFlowRate : 1;
SIG_VALTYPE_ 604 SystemFlags : 1;
SIG_VALTYPE_ 650 FrontTireTemperature : 1;
SIG_VALTYPE_ 650 RearTireTemperature : 1;
SIG_VALTYPE_ 651 FlexSensor1 : 1;
SIG_VALTYPE_ 651 FlexSensor2 : 1;
SIG_VALTYPE_ 652 FlexSensor3 : 1;
SIG_VALTYPE_ 653 SystemFlags : 1;
SIG_VALTYPE_ 859 SystemFlags : 1;
SIG_VALTYPE_ 845 CellTemp41 : 1;
SIG_VALTYPE_ 845 CellTemp42 : 1;
SIG_VALTYPE_ 846 CellTemp43 : 1;
SIG_VALTYPE_ 846 CellTemp44 : 1;
SIG_VALTYPE_ 847 CellTemp45 : 1;
SIG_VALTYPE_ 847 CellTemp46 : 1;
SIG_VALTYPE_ 848 CellTemp47 : 1;
SIG_VALTYPE_ 848 CellTemp48 : 1;
SIG_VALTYPE_ 485 RawThrottleInput : 1;
SIG_VALTYPE_ 825 CellTemp1 : 1;
SIG_VALTYPE_ 825 CellTemp2 : 1;
